# nrf54h20_enga_radiocore register map
Vendor: Nordic Semiconductor; Series: nRF54h; File version: 1
CPU: CM33 r0p4, little endian, MPU, FPU, 3 interrupt priority bits, 480 interrupts, 4 SAU regions
Registers are 32-bit, read-write, reset 0x0 unless marked. A register's access mark holds for its fields unless they carry their own. Offsets are from the block's base; [hi:lo] are bit positions; lines under a group give offsets from that group; {n}, {i} and the like mark numbered series; 'fields as' and 'values as' point back to an identical list.

## RADIOACC_NS — RADIOACC peripheral 0
Base 0x53033000
Same registers: RADIOACC_S 0x53033000 (alternate view of RADIOACC_NS)
0x00 TASKS_DMAA group — Peripheral tasks.
  0x00 START wo — Start the Task for DMA-A
    [0] START
      1=Trigger task
  0x04 STOP wo — Start the Task Stop for DMA-A
    [0] STOP
      1=Trigger task
  0x08 RESET wo — Start the Task Reset for DMA-A
    [0] RESET
      1=Trigger task
0x0C TASKS_DMAB group — Peripheral tasks.
  0x00 START wo — Start the Task for DMA-B
    [0] START
      1=Trigger task
  0x04 STOP wo — Start the Task Stop for DMA-B
    [0] STOP
      1=Trigger task
  0x08 RESET wo — Start the Task Reset for DMA-B
    [0] RESET
      1=Trigger task
0x18 TASKS_COMPUTESTART wo — Start Computation for ReConfAccHW Core
  [0] TASKS_COMPUTESTART
    1=Trigger task
0x1C TASKS_CONTROLEN wo — Start ReConfAccHW Control Unit
  [0] TASKS_CONTROLEN
    1=Trigger task
0x20 TASKS_ALLTASKSSTOP wo — Stop All Running Tasks
  [0] TASKS_ALLTASKSSTOP
    1=Trigger task
0x80 SUBSCRIBE_DMAA group — Subscribe configuration for tasks
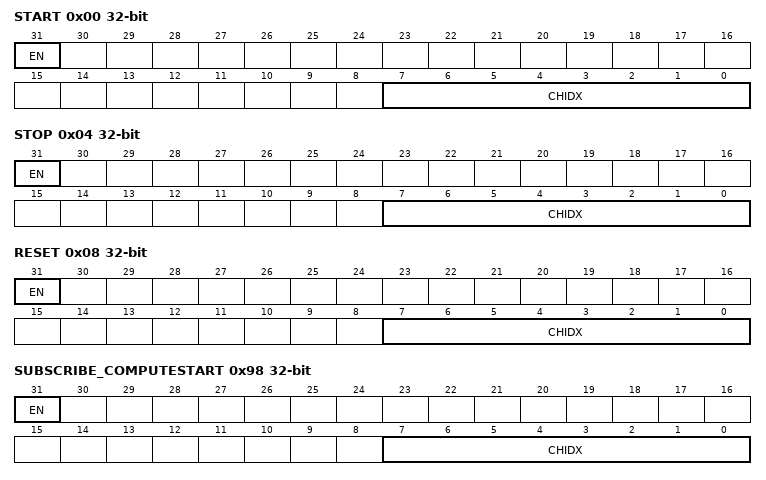
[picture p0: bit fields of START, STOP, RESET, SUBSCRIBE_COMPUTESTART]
  0x00 START — Subscribe configuration for task DMAA.START
    [31] EN
      0=Disabled (Disable subscription); 1=Enabled (Enable subscription)
    [7:0] CHIDX — DPPI channel that task DMAA.START will subscribe to
  0x04 STOP — Subscribe configuration for task DMAA.STOP
    [31] EN
      values as SUBSCRIBE_DMAA.START.EN
    [7:0] CHIDX — DPPI channel that task DMAA.STOP will subscribe to
  0x08 RESET — Subscribe configuration for task DMAA.RESET
    [31] EN
      values as SUBSCRIBE_DMAA.START.EN
    [7:0] CHIDX — DPPI channel that task DMAA.RESET will subscribe to
0x8C SUBSCRIBE_DMAB group — Subscribe configuration for tasks
  0x00 START — Subscribe configuration for task DMAB.START
    [31] EN
      values as SUBSCRIBE_DMAA.START.EN
    [7:0] CHIDX — DPPI channel that task DMAB.START will subscribe to
  0x04 STOP — Subscribe configuration for task DMAB.STOP
    [31] EN
      values as SUBSCRIBE_DMAA.START.EN
    [7:0] CHIDX — DPPI channel that task DMAB.STOP will subscribe to
  0x08 RESET — Subscribe configuration for task DMAB.RESET
    [31] EN
      values as SUBSCRIBE_DMAA.START.EN
    [7:0] CHIDX — DPPI channel that task DMAB.RESET will subscribe to
0x98 SUBSCRIBE_COMPUTESTART — Subscribe configuration for task COMPUTESTART
  [31] EN
    values as SUBSCRIBE_DMAA.START.EN
  [7:0] CHIDX — DPPI channel that task COMPUTESTART will subscribe to
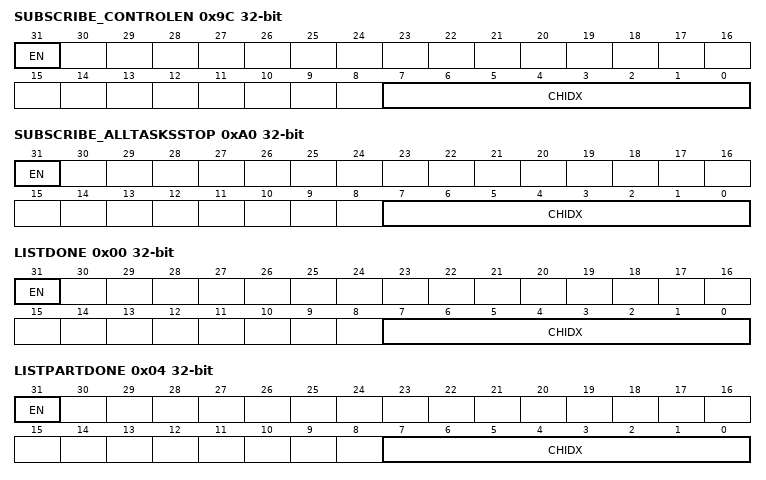
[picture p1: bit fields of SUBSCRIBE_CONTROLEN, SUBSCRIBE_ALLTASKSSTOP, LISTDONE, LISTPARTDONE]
0x9C SUBSCRIBE_CONTROLEN — Subscribe configuration for task CONTROLEN
  [31] EN
    values as SUBSCRIBE_DMAA.START.EN
  [7:0] CHIDX — DPPI channel that task CONTROLEN will subscribe to
0xA0 SUBSCRIBE_ALLTASKSSTOP — Subscribe configuration for task ALLTASKSSTOP
  [31] EN
    values as SUBSCRIBE_DMAA.START.EN
  [7:0] CHIDX — DPPI channel that task ALLTASKSSTOP will subscribe to
0x100 EVENTS_DMAA group — Peripheral events.
  0x00 LISTDONE — Event List Done DMA-A
    [0] LISTDONE
      0=NotGenerated (Event not generated); 1=Generated (Event generated)
  0x04 LISTPARTDONE — Event List Part Done DMA-A
    [0] LISTPARTDONE
      values as EVENTS_DMAA.LISTDONE.LISTDONE
  0x08 SELECTJOBDONE — Event List Select Job Done DMA-A
    [0] SELECTJOBDONE
      values as EVENTS_DMAA.LISTDONE.LISTDONE
  0x0C DATADONE — Event Data Done DMA-A
    [0] DATADONE
      values as EVENTS_DMAA.LISTDONE.LISTDONE
  0x10 JOBDONE — Event Job Done DMA-A
    [0] JOBDONE
      values as EVENTS_DMAA.LISTDONE.LISTDONE
  0x14 ERROR — Event Error DMA-A
    [0] ERROR
      values as EVENTS_DMAA.LISTDONE.LISTDONE
  0x18 STOP — Event Stop DMA-A
    [0] STOP
      values as EVENTS_DMAA.LISTDONE.LISTDONE
  0x1C RESET — Event Reset DMA-A
    [0] RESET
      values as EVENTS_DMAA.LISTDONE.LISTDONE
0x120 EVENTS_DMAB group — Peripheral events.
  0x00 LISTDONE — Event List Done DMA-B
    fields as EVENTS_DMAA.LISTDONE
  0x04 LISTPARTDONE — Event List Part Done DMA-B
    fields as EVENTS_DMAA.LISTPARTDONE
  0x08 SELECTJOBDONE — Event List Select Job Done DMA-B
    fields as EVENTS_DMAA.SELECTJOBDONE
  0x0C DATADONE — Event Data Done DMA-B
    fields as EVENTS_DMAA.DATADONE
  0x10 JOBDONE — Event Job Done DMA-B
    fields as EVENTS_DMAA.JOBDONE
  0x14 ERROR — Event Error DMA-B
    fields as EVENTS_DMAA.ERROR
  0x18 STOP — Event Stop DMA-B
    fields as EVENTS_DMAA.STOP
  0x1C RESET — Event Reset DMA-B
    fields as EVENTS_DMAA.RESET
0x140 EVENTS_COMPUTEEND — Event Compute End
  [0] EVENTS_COMPUTEEND
    values as EVENTS_DMAA.LISTDONE.LISTDONE
0x144 EVENTS_CTXFIFOEMPTY — Event Context Fifo Empty
  [0] EVENTS_CTXFIFOEMPTY
    values as EVENTS_DMAA.LISTDONE.LISTDONE
0x148 EVENTS_ALLTASKSSTOP — Event All Running Tasks Stop
  [0] EVENTS_ALLTASKSSTOP
    values as EVENTS_DMAA.LISTDONE.LISTDONE
0x180 PUBLISH_DMAA group — Publish configuration for events
  0x00 LISTDONE — Publish configuration for event DMAA.LISTDONE
    [31] EN
      0=Disabled (Disable publishing); 1=Enabled (Enable publishing)
    [7:0] CHIDX — DPPI channel that event DMAA.LISTDONE will publish to
  0x04 LISTPARTDONE — Publish configuration for event DMAA.LISTPARTDONE
    [31] EN
      values as PUBLISH_DMAA.LISTDONE.EN
    [7:0] CHIDX — DPPI channel that event DMAA.LISTPARTDONE will publish to
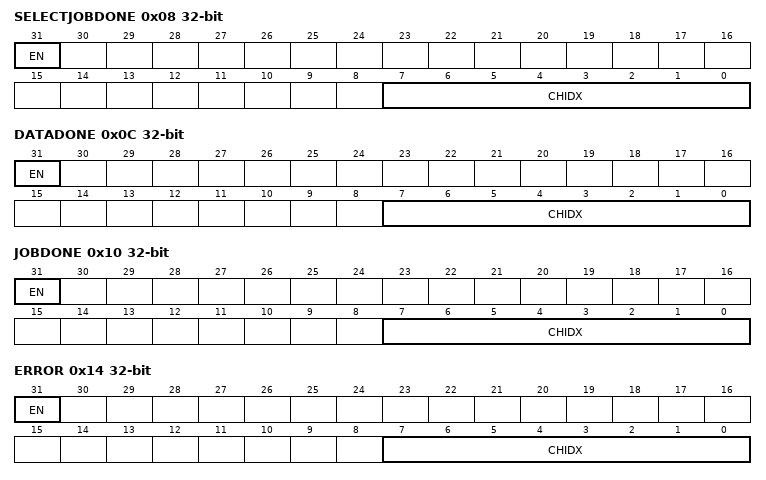
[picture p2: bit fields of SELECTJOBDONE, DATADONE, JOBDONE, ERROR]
  0x08 SELECTJOBDONE — Publish configuration for event DMAA.SELECTJOBDONE
    [31] EN
      values as PUBLISH_DMAA.LISTDONE.EN
    [7:0] CHIDX — DPPI channel that event DMAA.SELECTJOBDONE will publish to
  0x0C DATADONE — Publish configuration for event DMAA.DATADONE
    [31] EN
      values as PUBLISH_DMAA.LISTDONE.EN
    [7:0] CHIDX — DPPI channel that event DMAA.DATADONE will publish to
  0x10 JOBDONE — Publish configuration for event DMAA.JOBDONE
    [31] EN
      values as PUBLISH_DMAA.LISTDONE.EN
    [7:0] CHIDX — DPPI channel that event DMAA.JOBDONE will publish to
  0x14 ERROR — Publish configuration for event DMAA.ERROR
    [31] EN
      values as PUBLISH_DMAA.LISTDONE.EN
    [7:0] CHIDX — DPPI channel that event DMAA.ERROR will publish to
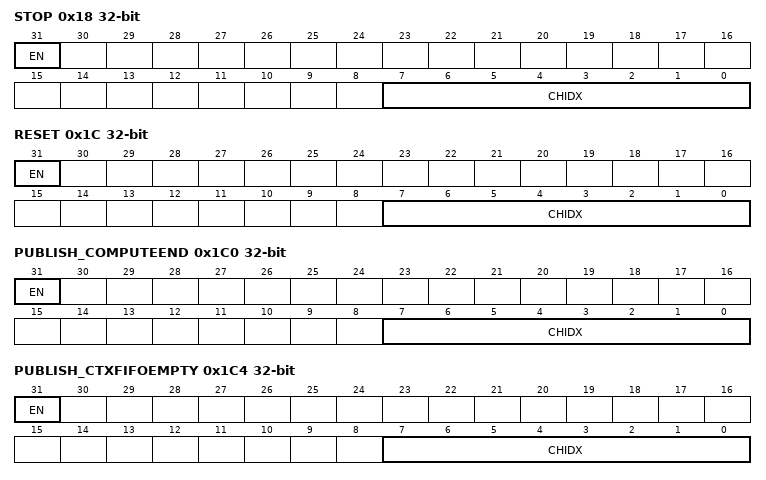
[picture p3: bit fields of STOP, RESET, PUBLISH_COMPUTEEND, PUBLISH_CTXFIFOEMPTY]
  0x18 STOP — Publish configuration for event DMAA.STOP
    [31] EN
      values as PUBLISH_DMAA.LISTDONE.EN
    [7:0] CHIDX — DPPI channel that event DMAA.STOP will publish to
  0x1C RESET — Publish configuration for event DMAA.RESET
    [31] EN
      values as PUBLISH_DMAA.LISTDONE.EN
    [7:0] CHIDX — DPPI channel that event DMAA.RESET will publish to
0x1A0 PUBLISH_DMAB group — Publish configuration for events
  0x00 LISTDONE — Publish configuration for event DMAB.LISTDONE
    [31] EN
      values as PUBLISH_DMAA.LISTDONE.EN
    [7:0] CHIDX — DPPI channel that event DMAB.LISTDONE will publish to
  0x04 LISTPARTDONE — Publish configuration for event DMAB.LISTPARTDONE
    [31] EN
      values as PUBLISH_DMAA.LISTDONE.EN
    [7:0] CHIDX — DPPI channel that event DMAB.LISTPARTDONE will publish to
  0x08 SELECTJOBDONE — Publish configuration for event DMAB.SELECTJOBDONE
    [31] EN
      values as PUBLISH_DMAA.LISTDONE.EN
    [7:0] CHIDX — DPPI channel that event DMAB.SELECTJOBDONE will publish to
  0x0C DATADONE — Publish configuration for event DMAB.DATADONE
    [31] EN
      values as PUBLISH_DMAA.LISTDONE.EN
    [7:0] CHIDX — DPPI channel that event DMAB.DATADONE will publish to
  0x10 JOBDONE — Publish configuration for event DMAB.JOBDONE
    [31] EN
      values as PUBLISH_DMAA.LISTDONE.EN
    [7:0] CHIDX — DPPI channel that event DMAB.JOBDONE will publish to
  0x14 ERROR — Publish configuration for event DMAB.ERROR
    [31] EN
      values as PUBLISH_DMAA.LISTDONE.EN
    [7:0] CHIDX — DPPI channel that event DMAB.ERROR will publish to
  0x18 STOP — Publish configuration for event DMAB.STOP
    [31] EN
      values as PUBLISH_DMAA.LISTDONE.EN
    [7:0] CHIDX — DPPI channel that event DMAB.STOP will publish to
  0x1C RESET — Publish configuration for event DMAB.RESET
    [31] EN
      values as PUBLISH_DMAA.LISTDONE.EN
    [7:0] CHIDX — DPPI channel that event DMAB.RESET will publish to
0x1C0 PUBLISH_COMPUTEEND — Publish configuration for event COMPUTEEND
  [31] EN
    values as PUBLISH_DMAA.LISTDONE.EN
  [7:0] CHIDX — DPPI channel that event COMPUTEEND will publish to
0x1C4 PUBLISH_CTXFIFOEMPTY — Publish configuration for event CTXFIFOEMPTY
  [31] EN
    values as PUBLISH_DMAA.LISTDONE.EN
  [7:0] CHIDX — DPPI channel that event CTXFIFOEMPTY will publish to
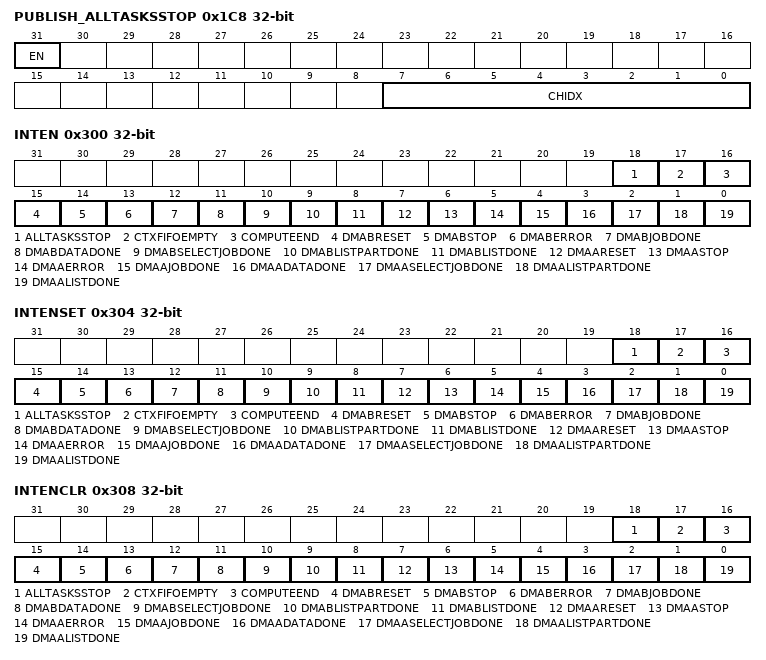
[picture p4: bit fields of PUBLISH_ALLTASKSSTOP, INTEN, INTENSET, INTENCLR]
0x1C8 PUBLISH_ALLTASKSSTOP — Publish configuration for event ALLTASKSSTOP
  [31] EN
    values as PUBLISH_DMAA.LISTDONE.EN
  [7:0] CHIDX — DPPI channel that event ALLTASKSSTOP will publish to
0x300 INTEN — Enable or disable interrupt
  [all] fields
    0=Disabled; 1=Enabled
  [18] ALLTASKSSTOP — Enable or disable interrupt for event ALLTASKSSTOP
  [17] CTXFIFOEMPTY — Enable or disable interrupt for event CTXFIFOEMPTY
  [16] COMPUTEEND — Enable or disable interrupt for event COMPUTEEND
  [15] DMABRESET — Enable or disable interrupt for event DMABRESET
  [14] DMABSTOP — Enable or disable interrupt for event DMABSTOP
  [13] DMABERROR — Enable or disable interrupt for event DMABERROR
  [12] DMABJOBDONE — Enable or disable interrupt for event DMABJOBDONE
  [11] DMABDATADONE — Enable or disable interrupt for event DMABDATADONE
  [10] DMABSELECTJOBDONE — Enable or disable interrupt for event DMABSELECTJOBDONE
  [9] DMABLISTPARTDONE — Enable or disable interrupt for event DMABLISTPARTDONE
  [8] DMABLISTDONE — Enable or disable interrupt for event DMABLISTDONE
  [7] DMAARESET — Enable or disable interrupt for event DMAARESET
  [6] DMAASTOP — Enable or disable interrupt for event DMAASTOP
  [5] DMAAERROR — Enable or disable interrupt for event DMAAERROR
  [4] DMAAJOBDONE — Enable or disable interrupt for event DMAAJOBDONE
  [3] DMAADATADONE — Enable or disable interrupt for event DMAADATADONE
  [2] DMAASELECTJOBDONE — Enable or disable interrupt for event DMAASELECTJOBDONE
  [1] DMAALISTPARTDONE — Enable or disable interrupt for event DMAALISTPARTDONE
  [0] DMAALISTDONE — Enable or disable interrupt for event DMAALISTDONE
0x304 INTENSET — Enable interrupt
  [all] fields
    on read: 0=Disabled (Read: Disabled); 1=Enabled (Read: Enabled) | on write: 1=Set (Enable)
  [18] ALLTASKSSTOP — Write '1' to enable interrupt for event ALLTASKSSTOP
  [17] CTXFIFOEMPTY — Write '1' to enable interrupt for event CTXFIFOEMPTY
  [16] COMPUTEEND — Write '1' to enable interrupt for event COMPUTEEND
  [15] DMABRESET — Write '1' to enable interrupt for event DMABRESET
  [14] DMABSTOP — Write '1' to enable interrupt for event DMABSTOP
  [13] DMABERROR — Write '1' to enable interrupt for event DMABERROR
  [12] DMABJOBDONE — Write '1' to enable interrupt for event DMABJOBDONE
  [11] DMABDATADONE — Write '1' to enable interrupt for event DMABDATADONE
  [10] DMABSELECTJOBDONE — Write '1' to enable interrupt for event DMABSELECTJOBDONE
  [9] DMABLISTPARTDONE — Write '1' to enable interrupt for event DMABLISTPARTDONE
  [8] DMABLISTDONE — Write '1' to enable interrupt for event DMABLISTDONE
  [7] DMAARESET — Write '1' to enable interrupt for event DMAARESET
  [6] DMAASTOP — Write '1' to enable interrupt for event DMAASTOP
  [5] DMAAERROR — Write '1' to enable interrupt for event DMAAERROR
  [4] DMAAJOBDONE — Write '1' to enable interrupt for event DMAAJOBDONE
  [3] DMAADATADONE — Write '1' to enable interrupt for event DMAADATADONE
  [2] DMAASELECTJOBDONE — Write '1' to enable interrupt for event DMAASELECTJOBDONE
  [1] DMAALISTPARTDONE — Write '1' to enable interrupt for event DMAALISTPARTDONE
  [0] DMAALISTDONE — Write '1' to enable interrupt for event DMAALISTDONE
0x308 INTENCLR — Disable interrupt
  [all] fields
    on read: 0=Disabled (Read: Disabled); 1=Enabled (Read: Enabled) | on write: 1=Clear (Disable)
  [18] ALLTASKSSTOP — Write '1' to disable interrupt for event ALLTASKSSTOP
  [17] CTXFIFOEMPTY — Write '1' to disable interrupt for event CTXFIFOEMPTY
  [16] COMPUTEEND — Write '1' to disable interrupt for event COMPUTEEND
  [15] DMABRESET — Write '1' to disable interrupt for event DMABRESET
  [14] DMABSTOP — Write '1' to disable interrupt for event DMABSTOP
  [13] DMABERROR — Write '1' to disable interrupt for event DMABERROR
  [12] DMABJOBDONE — Write '1' to disable interrupt for event DMABJOBDONE
  [11] DMABDATADONE — Write '1' to disable interrupt for event DMABDATADONE
  [10] DMABSELECTJOBDONE — Write '1' to disable interrupt for event DMABSELECTJOBDONE
  [9] DMABLISTPARTDONE — Write '1' to disable interrupt for event DMABLISTPARTDONE
  [8] DMABLISTDONE — Write '1' to disable interrupt for event DMABLISTDONE
  [7] DMAARESET — Write '1' to disable interrupt for event DMAARESET
  [6] DMAASTOP — Write '1' to disable interrupt for event DMAASTOP
  [5] DMAAERROR — Write '1' to disable interrupt for event DMAAERROR
  [4] DMAAJOBDONE — Write '1' to disable interrupt for event DMAAJOBDONE
  [3] DMAADATADONE — Write '1' to disable interrupt for event DMAADATADONE
  [2] DMAASELECTJOBDONE — Write '1' to disable interrupt for event DMAASELECTJOBDONE
  [1] DMAALISTPARTDONE — Write '1' to disable interrupt for event DMAALISTPARTDONE
  [0] DMAALISTDONE — Write '1' to disable interrupt for event DMAALISTDONE
0x400 SWRST — Software-based Reset
  [0] State
    0=Active Low State; 1=Active High State
0x404 AUTO — Mode of Computation
  [0] MODE
    0=Non Active Mode of Computation; 1=Active Mode of Computation
0x408 CTRLWORD group — Unspecified
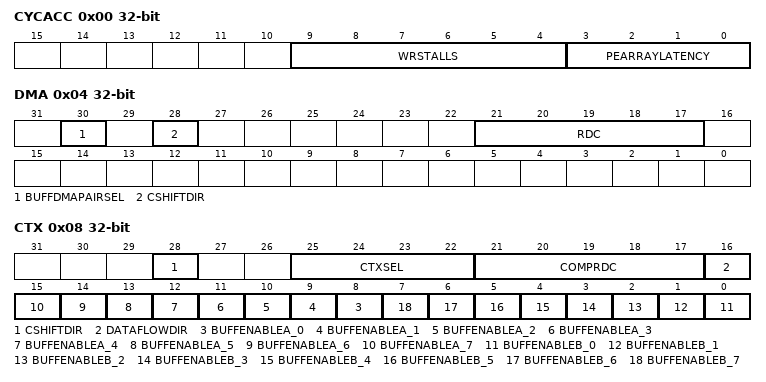
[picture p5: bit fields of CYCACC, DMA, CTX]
  0x00 CYCACC — Bit fields required for Cycle Accurate processing, i.e., Write Stalls and Cell Array Latency
    [9:4] WRSTALLS — Write Stalls
    [3:0] PEARRAYLATENCY — Latency of the cell array
  0x04 DMA — Bit fields required for cycle accurate processing.
    [30] BUFFDMAPAIRSEL — Buffer and DMA Pairing Selection
      0=PairSelectNormal (DMA-A Writes to Buffer 0 and DMA-B Reads from Buffer 1); 1=PairSelectFlip (DMA-A Writes to Buffer 1 and DMA-B Reads from Buffer 0)
    [28] CSHIFTDIR — Cyclic Shift Direction in the Data Buffer
      0=CyclicDownwards; 1=CyclicUpwards
    [21:17] RDC — Active Cycles of DMA for data to be Written/Read from the CR of a Data Buffer.
  0x08 CTX — The register address points to Control Word FIFO in the PAR block. It contains bit fields required for cycle accurate processing.
    [28] CSHIFTDIR — Cyclic Shift Direction in the Data Buffer
      0=CyclicDownwards; 1=CyclicUpwards
    [25:22] CTXSEL — Context Select
    [21:17] COMPRDC — Cycles required for the computation.
    [16] DATAFLOWDIR — Direction of Data Flow over the Cell Array
      0=TopToBottom (From top to bottom); 1=BottomToTop (From bottom to top)
    [n+8] BUFFENABLEA_{n} (n=0..7) — Enable Bit for CR{n} in HW Data Buffer A
      0=Disable; 1=Enable
    [n] BUFFENABLEB_{n} (n=0..7) — Enable Bit for CR{n} in HW Data Buffer B
      0=Disable; 1=Enable
0x604 DMAA group — Unspecified
  0x00 LISTPTR — Register address to store the Data Pointer of the Job List for DMA-A
    [31:0] ADDRESS — Pointer to Job List for DMA-A
  0x04 LISTPARTTHRESH — Threshold value for generating event EVENTS_DMMA.LISTPARTDONE when descriptor list is partially completed. Value is number of jobs.
    [15:0] LISTPARTTHRESH — Threshold value.
0x624 DMAB group — Unspecified
  0x00 LISTPTR — Register address to store the Data Pointer of the Job List for DMA-B
    [31:0] ADDRESS — Pointer to Job List for DMA-B
  0x04 LISTPARTTHRESH — Threshold value for generating event EVENTS_DMAB.LISTPARTDONE when descriptor list is partially completed. Value is number of jobs.
    [15:0] LISTPARTTHRESH — Threshold value.
